# V32F20x_CM33 register map
File version: 1.0.3
CPU: CM33 r0p4, little endian, MPU, FPU, DSP, 3 interrupt priority bits, 8 SAU regions
Registers are 32-bit, read-write, reset 0x0 unless marked. A register's access mark holds for its fields unless they carry their own. Offsets are from the block's base; [hi:lo] are bit positions; {n}, {i} and the like mark numbered series.

## BTMR0 — BTMR0 Peripheral Interface
Base 0x40050000
Same registers: BTMR1 0x40050020, BTMR2 0x40050040, BTMR3 0x40050060, LPBTMR0 0x40108000, LPBTMR1 0x40109000, BTMR4 0x41050000, BTMR5 0x41050020, BTMR6 0x41050040, BTMR7 0x41050060, SEC_BTMR0 0x50050000, SEC_BTMR1 0x50050020, SEC_BTMR2 0x50050040, SEC_BTMR3 0x50050060, SEC_LPBTMR0 0x50108000, SEC_LPBTMR1 0x50109000
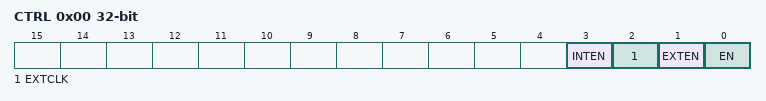
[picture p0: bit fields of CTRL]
0x00 CTRL — Timer0 control register.
  [3] INTEN — Timerx interrupt enable register.
  [2] EXTCLK — Select the external clock signal as the clock source
  [1] EXTEN — Select Timer external clock pin as the clock enable IO port
  [0] EN — Timerx enable control register.
0x04 VALUE — Timer0 real time counting register.
  [31:0] VALUE — Timerx real time counter register.
0x08 RELOAD — Timer0 reloads register.
  [31:0] RELOAD — Timerx reloads register
0x0C INTSTS — Timer0 interrupt status register.
  [0] INTSTS — Timerx interrupt status register.

## BPWM0 — BPWM0 Peripheral Interface
Base 0x40050100
Same registers: BPWM1 0x40050120, BPWM2 0x40050140, BPWM3 0x40050160, BPWM4 0x41050100, BPWM5 0x41050120, BPWM6 0x41050140, BPWM7 0x41050160, SEC_BPWM0 0x50050100, SEC_BPWM1 0x50050120, SEC_BPWM2 0x50050140, SEC_BPWM3 0x50050160
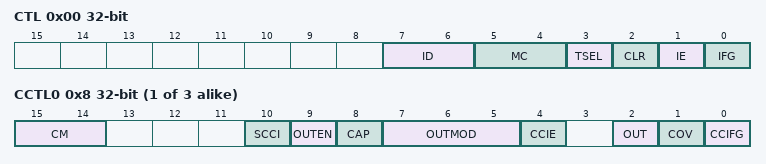
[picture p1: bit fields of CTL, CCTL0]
0x00 CTL — BPWM Timer control register.
  [7:6] ID — PWM Timerx input clock divide control.
  [5:4] MC — PWM Timer control.
  [3] TSEL — Clock source selected
  [2] CLR — TAR clear register
  [1] IE — PWM Timerx interrupt enable register.
  [0] IFG — PWM Timerx interrupt status flag bit
0x04 TAR ro — BPWM Timer real time counting register.
  [31:0] TAR — PWM Timerx real time counting register.
{0x8+4i} CCTL{i} (i=0..2) — BPWM Timer compare/capture control register.
  [15:14] CM — Capture edge selection.
  [10] SCCI — When TAR is equal to CCRx the electricity level status of current channel input pins
  [9] OUTEN — OUTx output enable control register.
  [8] CAP — Capture/compare mode selection.
  [7:5] OUTMOD — Output mode selection.
  [4] CCIE — Capture /compare interrupt enable register.
  [2] OUT — When OUTMOD set 0 the bit is used to control the output value of OUTx
  [1] COV — Capture overflows flag bit
  [0] CCIFG — Under the capture mode when capture event happened the bit will set 1 and TAR will be locked in CCRx
{0x14+4i} CCR{i} (i=0..2) — BPWM Timer compare/ capture data register .
  [15:0] CCRx — Compare / capture data register

## BPWMMUX0 — BPWMMUX0 Peripheral Interface
Base 0x400501F0
Same registers: BPWMMUX1 0x410501F0, SEC_BPWMMUX0 0x500501F0
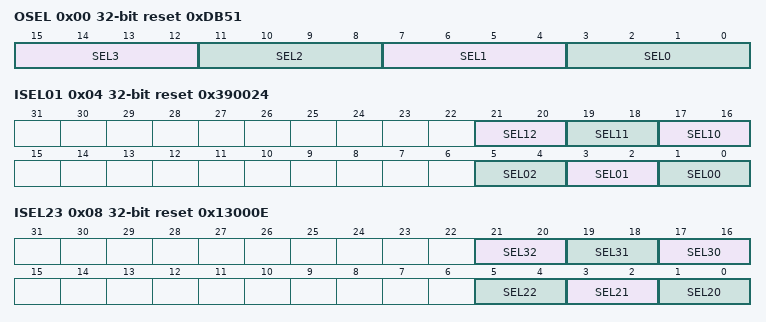
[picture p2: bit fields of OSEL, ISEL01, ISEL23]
0x00 OSEL reset 0xDB51 — BPWM output select register.
  [15:12] SEL3 — External output pin selected register for PWM3
  [11:8] SEL2 — External output pin selected register for PWM2
  [7:4] SEL1 — External output pin selected register for PWM1
  [3:0] SEL0 — External output pin selected register for PWM0.
0x04 ISEL01 reset 0x390024 — BPWM0 BPWM1 input select register.
  [21:20] SEL12 — The external input control of PWM1 channel 2 IN2
  [19:18] SEL11 — The external input control of PWM1 channel 1 IN1
  [17:16] SEL10 — The external output control of PWM1 channel 0 IN0
  [5:4] SEL02 — The external input control of PWM0 channel 2 IN2
  [3:2] SEL01 — The external input control of PWM0 channel 1 IN1
  [1:0] SEL00 — The external input control of PWM0 channel 0 IN0
0x08 ISEL23 reset 0x13000E — BPWM2 BPWM3 input select register.
  [21:20] SEL32 — The external input control of PWM3 channel 2 IN2
  [19:18] SEL31 — The external input control of PWM3 channel 1 IN1
  [17:16] SEL30 — The external input control of PWM3 channle 0 IN0
  [5:4] SEL22 — The external input control of PWM2 channel 2 IN2
  [3:2] SEL21 — The external input control of PWM2 channel 1 IN1
  [1:0] SEL20 — The external input control of PWM2 channel 0 IN0
